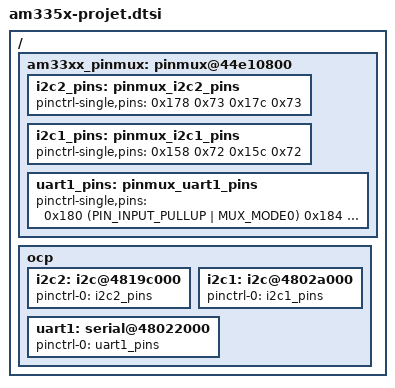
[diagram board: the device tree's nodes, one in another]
/ {
	am33xx_pinmux: pinmux@44e10800 
	{
		pinctrl-names = "default";
		i2c2_pins: pinmux_i2c2_pins 
		{
			pinctrl-single,pins = <0x178 0x73 0x17c 0x73>;
		};

		i2c1_pins: pinmux_i2c1_pins 
		{
			pinctrl-single,pins = <0x158 0x72 0x15c 0x72>;
		};
		uart1_pins: pinmux_uart1_pins 
			{
				pinctrl-single,pins = <
				0x180 (PIN_INPUT_PULLUP | MUX_MODE0) /*uart1 Rx : pin 26*/
				0x184 (PIN_OUTPUT_PULLDOWN | MUX_MODE0) /*uart1 Tx : pin 24*/
				>;
			};
	};
	ocp {
		i2c2: i2c@4819c000 
		{
			pinctrl-names = "default";
			pinctrl-0 = <&i2c2_pins>;
			status = "okay";
		};

		i2c1: i2c@4802a000 
		{
			pinctrl-names = "default";
			pinctrl-0 = <&i2c1_pins>;
			status = "okay";
		};



		uart1: serial@48022000
		{
			pinctrl-names = "default";
			pinctrl-0 = <&uart1_pins>;
			status = "okay";
		};
	} ;
} ;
